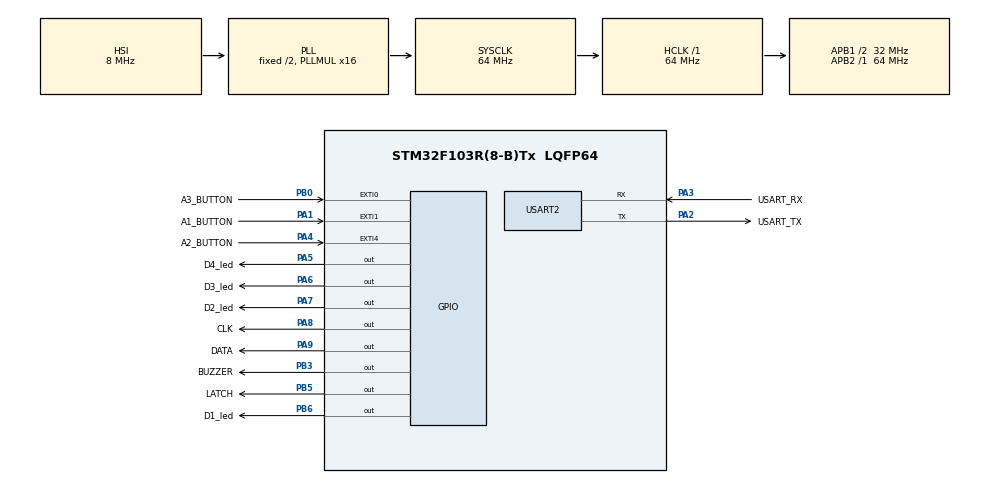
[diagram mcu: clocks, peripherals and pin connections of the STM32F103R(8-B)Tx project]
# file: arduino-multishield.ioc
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Mcu.Family=STM32F1
Mcu.Name=STM32F103R(8-B)Tx
Mcu.Package=LQFP64
NVIC.EXTI0_IRQn=true\:0\:0\:false\:false\:true\:true\:true\:true
NVIC.EXTI1_IRQn=true\:0\:0\:false\:false\:true\:true\:true\:true
NVIC.EXTI4_IRQn=true\:0\:0\:false\:false\:true\:true\:true\:true
NVIC.PriorityGroup=NVIC_PRIORITYGROUP_4
NVIC.TIM2_IRQn=true\:0\:0\:false\:false\:true\:true\:true\:true
NVIC.TIM3_IRQn=true\:0\:0\:false\:false\:true\:true\:true\:true
PA1.GPIO_Label=A1_BUTTON
PA1.GPIO_ModeDefaultEXTI=GPIO_MODE_IT_FALLING
PA1.GPIO_PuPd=GPIO_PULLUP
PA1.Signal=GPXTI1
PA13.GPIO_Label=TMS
PA13.Mode=Serial_Wire
PA13.Signal=SYS_JTMS-SWDIO
PA14.GPIO_Label=TCK
PA14.Mode=Serial_Wire
PA14.Signal=SYS_JTCK-SWCLK
PA2.GPIO_Label=USART_TX
PA2.GPIO_Mode=GPIO_MODE_AF_PP
PA2.GPIO_PuPd=GPIO_NOPULL
PA2.GPIO_Speed=GPIO_SPEED_FREQ_LOW
PA2.Mode=Asynchronous
PA2.Signal=USART2_TX
PA3.GPIO_Label=USART_RX
PA3.GPIO_Mode=GPIO_MODE_AF_PP
PA3.GPIO_PuPd=GPIO_NOPULL
PA3.GPIO_Speed=GPIO_SPEED_FREQ_LOW
PA3.Mode=Asynchronous
PA3.Signal=USART2_RX
PA4.GPIO_Label=A2_BUTTON
PA4.GPIO_ModeDefaultEXTI=GPIO_MODE_IT_FALLING
PA4.GPIO_PuPd=GPIO_PULLUP
PA4.Signal=GPXTI4
PA5.GPIO_Label=D4_led
PA5.GPIO_PuPd=GPIO_PULLDOWN
PA5.PinState=GPIO_PIN_SET
PA5.Signal=GPIO_Output
PA6.GPIO_Label=D3_led
PA6.GPIO_PuPd=GPIO_PULLDOWN
PA6.PinState=GPIO_PIN_SET
PA6.Signal=GPIO_Output
PA7.GPIO_Label=D2_led
PA7.GPIO_PuPd=GPIO_PULLDOWN
PA7.PinState=GPIO_PIN_SET
PA7.Signal=GPIO_Output
PA8.GPIO_Label=CLK
PA8.Signal=GPIO_Output
PA9.GPIO_Label=DATA
PA9.Signal=GPIO_Output
PB0.GPIO_Label=A3_BUTTON
PB0.GPIO_ModeDefaultEXTI=GPIO_MODE_IT_FALLING
PB0.GPIO_PuPd=GPIO_PULLUP
PB0.Signal=GPXTI0
PB3.GPIO_Label=BUZZER
PB3.GPIO_ModeDefaultOutputPP=GPIO_MODE_OUTPUT_OD
PB3.GPIO_PuPd=GPIO_NOPULL
PB3.PinState=GPIO_PIN_SET
PB3.Signal=GPIO_Output
PB5.GPIO_Label=LATCH
PB5.Signal=GPIO_Output
PB6.GPIO_Label=D1_led
PB6.GPIO_PuPd=GPIO_PULLDOWN
PB6.PinState=GPIO_PIN_SET
PB6.Signal=GPIO_Output
PC14-OSC32_IN.Mode=LSE-External-Oscillator
PC14-OSC32_IN.Signal=RCC_OSC32_IN
PC15-OSC32_OUT.Mode=LSE-External-Oscillator
PC15-OSC32_OUT.Signal=RCC_OSC32_OUT
PD0-OSC_IN.Mode=HSE-External-Oscillator
PD0-OSC_IN.Signal=RCC_OSC_IN
PD1-OSC_OUT.Mode=HSE-External-Oscillator
PD1-OSC_OUT.Signal=RCC_OSC_OUT
ProjectManager.HeapSize=0x200
ProjectManager.StackSize=0x400
ProjectManager.TargetToolchain=MDK-ARM V5.32
RCC.AHBFreq_Value=64000000
RCC.APB1CLKDivider=RCC_HCLK_DIV2
RCC.APB1Freq_Value=32000000
RCC.APB1TimFreq_Value=64000000
RCC.APB2Freq_Value=64000000
RCC.APB2TimFreq_Value=64000000
RCC.HCLKFreq_Value=64000000
RCC.PLLMUL=RCC_PLL_MUL16
RCC.RTCClockSelection=RCC_RTCCLKSOURCE_LSE
RCC.SYSCLKFreq_VALUE=64000000
RCC.SYSCLKSource=RCC_SYSCLKSOURCE_PLLCLK
RCC.USBFreq_Value=64000000
TIM2.Period=63999
TIM2.Prescaler=999
TIM3.Period=6399
TIM3.Prescaler=999
USART2.VirtualMode=VM_ASYNC
VP_TIM2_VS_ClockSourceINT.Mode=Internal
VP_TIM3_VS_ClockSourceINT.Mode=Internal
board=NUCLEO-F103RB

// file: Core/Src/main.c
/* USER CODE BEGIN Header */
/**
  ******************************************************************************
  * @file           : main.c
  * @brief          : Main program body
  ******************************************************************************
  * @attention
  *
  * Copyright (c) 2025 STMicroelectronics.
  * All rights reserved.
  *
  * This software is licensed under terms that can be found in the LICENSE file
  * in the root directory of this software component.
  * If no LICENSE file comes with this software, it is provided AS-IS.
  *
  ******************************************************************************
  */
/* USER CODE END Header */
#include "main.h"
#include "tim.h"
#include "usart.h"
#include "gpio.h"

/* USER CODE BEGIN Includes */
#include "mfs.h"
/* USER CODE END Includes */

void SystemClock_Config(void);

int main(void)
{

  /* MCU Configuration--------------------------------------------------------*/

  /* Reset of all peripherals, Initializes the Flash interface and the Systick. */
  HAL_Init();

  /* Configure the system clock */
  SystemClock_Config();

  /* Initialize all configured peripherals */
  MX_GPIO_Init();
  MX_TIM2_Init();
  MX_USART2_UART_Init();
  MX_TIM3_Init();

  /* Infinite loop */
  /* USER CODE BEGIN WHILE */
	MFS_DisplayNumber(display_number);
	last_click_ticks = HAL_GetTick();
	HAL_TIM_Base_Start_IT(&htim3);

	while (1)
  {
		if(timer_ended)
		{
			HAL_TIM_Base_Stop_IT(&htim2);
			timer_ended = false;
			MFS_DisplayStop();
			MFS_SET_LEDS(GPIO_PIN_RESET);
		}
		MFS_RefreshDisplay();
    /* USER CODE END WHILE */

  }
}

void SystemClock_Config(void)
{
  RCC_OscInitTypeDef RCC_OscInitStruct = {0};
  RCC_ClkInitTypeDef RCC_ClkInitStruct = {0};

  /** Initializes the RCC Oscillators according to the specified parameters
  * in the RCC_OscInitTypeDef structure.
  */
  RCC_OscInitStruct.OscillatorType = RCC_OSCILLATORTYPE_HSI;
  RCC_OscInitStruct.HSIState = RCC_HSI_ON;
  RCC_OscInitStruct.HSICalibrationValue = RCC_HSICALIBRATION_DEFAULT;
  RCC_OscInitStruct.PLL.PLLState = RCC_PLL_ON;
  RCC_OscInitStruct.PLL.PLLSource = RCC_PLLSOURCE_HSI_DIV2;
  RCC_OscInitStruct.PLL.PLLMUL = RCC_PLL_MUL16;
  if (HAL_RCC_OscConfig(&RCC_OscInitStruct) != HAL_OK)
  {
    Error_Handler();
  }

  /** Initializes the CPU, AHB and APB buses clocks
  */
  RCC_ClkInitStruct.ClockType = RCC_CLOCKTYPE_HCLK|RCC_CLOCKTYPE_SYSCLK
                              |RCC_CLOCKTYPE_PCLK1|RCC_CLOCKTYPE_PCLK2;
  RCC_ClkInitStruct.SYSCLKSource = RCC_SYSCLKSOURCE_PLLCLK;
  RCC_ClkInitStruct.AHBCLKDivider = RCC_SYSCLK_DIV1;
  RCC_ClkInitStruct.APB1CLKDivider = RCC_HCLK_DIV2;
  RCC_ClkInitStruct.APB2CLKDivider = RCC_HCLK_DIV1;

  if (HAL_RCC_ClockConfig(&RCC_ClkInitStruct, FLASH_LATENCY_2) != HAL_OK)
  {
    Error_Handler();
  }
}

void Error_Handler(void)
{
  __disable_irq();
  while (1)
  {
  }
}
